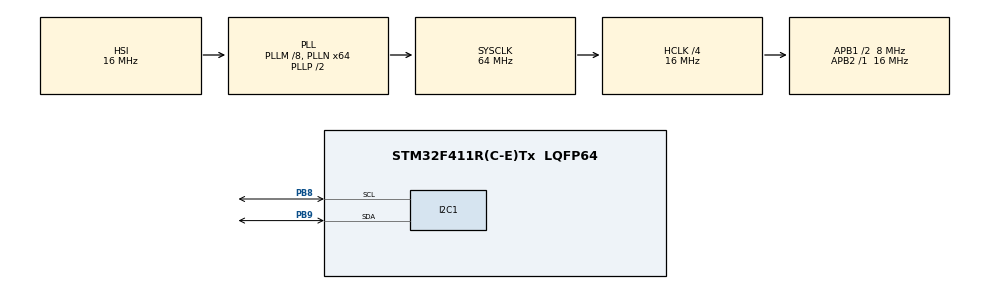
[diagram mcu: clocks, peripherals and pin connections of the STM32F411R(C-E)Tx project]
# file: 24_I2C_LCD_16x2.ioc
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I2C1.I2C_Mode=I2C_Fast
I2C1.NoStretchMode=I2C_NOSTRETCH_DISABLE
Mcu.Family=STM32F4
Mcu.Name=STM32F411R(C-E)Tx
Mcu.Package=LQFP64
NVIC.PriorityGroup=NVIC_PRIORITYGROUP_0
PB8.Mode=I2C
PB8.Signal=I2C1_SCL
PB9.Mode=I2C
PB9.Signal=I2C1_SDA
ProjectManager.HeapSize=0x200
ProjectManager.StackSize=0x400
ProjectManager.TargetToolchain=STM32CubeIDE
RCC.48MHZClocksFreq_Value=32000000
RCC.AHBCLKDivider=RCC_SYSCLK_DIV4
RCC.AHBFreq_Value=16000000
RCC.APB1CLKDivider=RCC_HCLK_DIV2
RCC.APB1Freq_Value=8000000
RCC.APB1TimFreq_Value=16000000
RCC.APB2Freq_Value=16000000
RCC.APB2TimFreq_Value=16000000
RCC.CortexFreq_Value=16000000
RCC.FLatency-AdvancedSettings=FLASH_LATENCY_0
RCC.HCLKFreq_Value=16000000
RCC.HSE_VALUE=8000000
RCC.HSI_VALUE=16000000
RCC.PLLM=8
RCC.PLLN=64
RCC.SYSCLKFreq_VALUE=64000000
RCC.SYSCLKSource=RCC_SYSCLKSOURCE_PLLCLK
RCC.VCOOutputFreq_Value=128000000
board=NUCLEO-F411RE

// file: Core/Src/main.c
/* USER CODE BEGIN Header */
/**
  ******************************************************************************
  * @file           : main.c
  * @brief          : Main program body
  ******************************************************************************
  * @attention
  *
  * Copyright (c) 2025 STMicroelectronics.
  * All rights reserved.
  *
  * This software is licensed under terms that can be found in the LICENSE file
  * in the root directory of this software component.
  * If no LICENSE file comes with this software, it is provided AS-IS.
  *
  ******************************************************************************
  */
/* USER CODE END Header */
#include "main.h"
#include "i2c.h"
#include "gpio.h"

/* USER CODE BEGIN Includes */
#include "i2c_lcd.h"
/* USER CODE END Includes */

void SystemClock_Config(void);

int main(void)
{

  /* MCU Configuration--------------------------------------------------------*/

  /* Reset of all peripherals, Initializes the Flash interface and the Systick. */
  HAL_Init();

  /* Configure the system clock */
  SystemClock_Config();

  /* Initialize all configured peripherals */
  MX_GPIO_Init();
  MX_I2C1_Init();
  /* USER CODE BEGIN 2 */
  lcd_init();
  /* USER CODE END 2 */

  /* Infinite loop */
  while (1)
  {

    /* USER CODE BEGIN 3 */
	  lcd_put_cursor(0,0);
	  lcd_send_string("Hello World!");
	  lcd_put_cursor(1,0);
	  lcd_send_string("From STM32Nucleo");
	  HAL_Delay(50);

  }
  /* USER CODE END 3 */
}

void SystemClock_Config(void)
{
  RCC_OscInitTypeDef RCC_OscInitStruct = {0};
  RCC_ClkInitTypeDef RCC_ClkInitStruct = {0};

  /** Configure the main internal regulator output voltage
  */
  __HAL_RCC_PWR_CLK_ENABLE();
  __HAL_PWR_VOLTAGESCALING_CONFIG(PWR_REGULATOR_VOLTAGE_SCALE1);

  /** Initializes the RCC Oscillators according to the specified parameters
  * in the RCC_OscInitTypeDef structure.
  */
  RCC_OscInitStruct.OscillatorType = RCC_OSCILLATORTYPE_HSI;
  RCC_OscInitStruct.HSIState = RCC_HSI_ON;
  RCC_OscInitStruct.HSICalibrationValue = RCC_HSICALIBRATION_DEFAULT;
  RCC_OscInitStruct.PLL.PLLState = RCC_PLL_ON;
  RCC_OscInitStruct.PLL.PLLSource = RCC_PLLSOURCE_HSI;
  RCC_OscInitStruct.PLL.PLLM = 8;
  RCC_OscInitStruct.PLL.PLLN = 64;
  RCC_OscInitStruct.PLL.PLLP = RCC_PLLP_DIV2;
  RCC_OscInitStruct.PLL.PLLQ = 4;
  if (HAL_RCC_OscConfig(&RCC_OscInitStruct) != HAL_OK)
  {
    Error_Handler();
  }

  /** Initializes the CPU, AHB and APB buses clocks
  */
  RCC_ClkInitStruct.ClockType = RCC_CLOCKTYPE_HCLK|RCC_CLOCKTYPE_SYSCLK
                              |RCC_CLOCKTYPE_PCLK1|RCC_CLOCKTYPE_PCLK2;
  RCC_ClkInitStruct.SYSCLKSource = RCC_SYSCLKSOURCE_PLLCLK;
  RCC_ClkInitStruct.AHBCLKDivider = RCC_SYSCLK_DIV4;
  RCC_ClkInitStruct.APB1CLKDivider = RCC_HCLK_DIV2;
  RCC_ClkInitStruct.APB2CLKDivider = RCC_HCLK_DIV1;

  if (HAL_RCC_ClockConfig(&RCC_ClkInitStruct, FLASH_LATENCY_0) != HAL_OK)
  {
    Error_Handler();
  }
}

void Error_Handler(void)
{
  __disable_irq();
  while (1)
  {
  }
}
